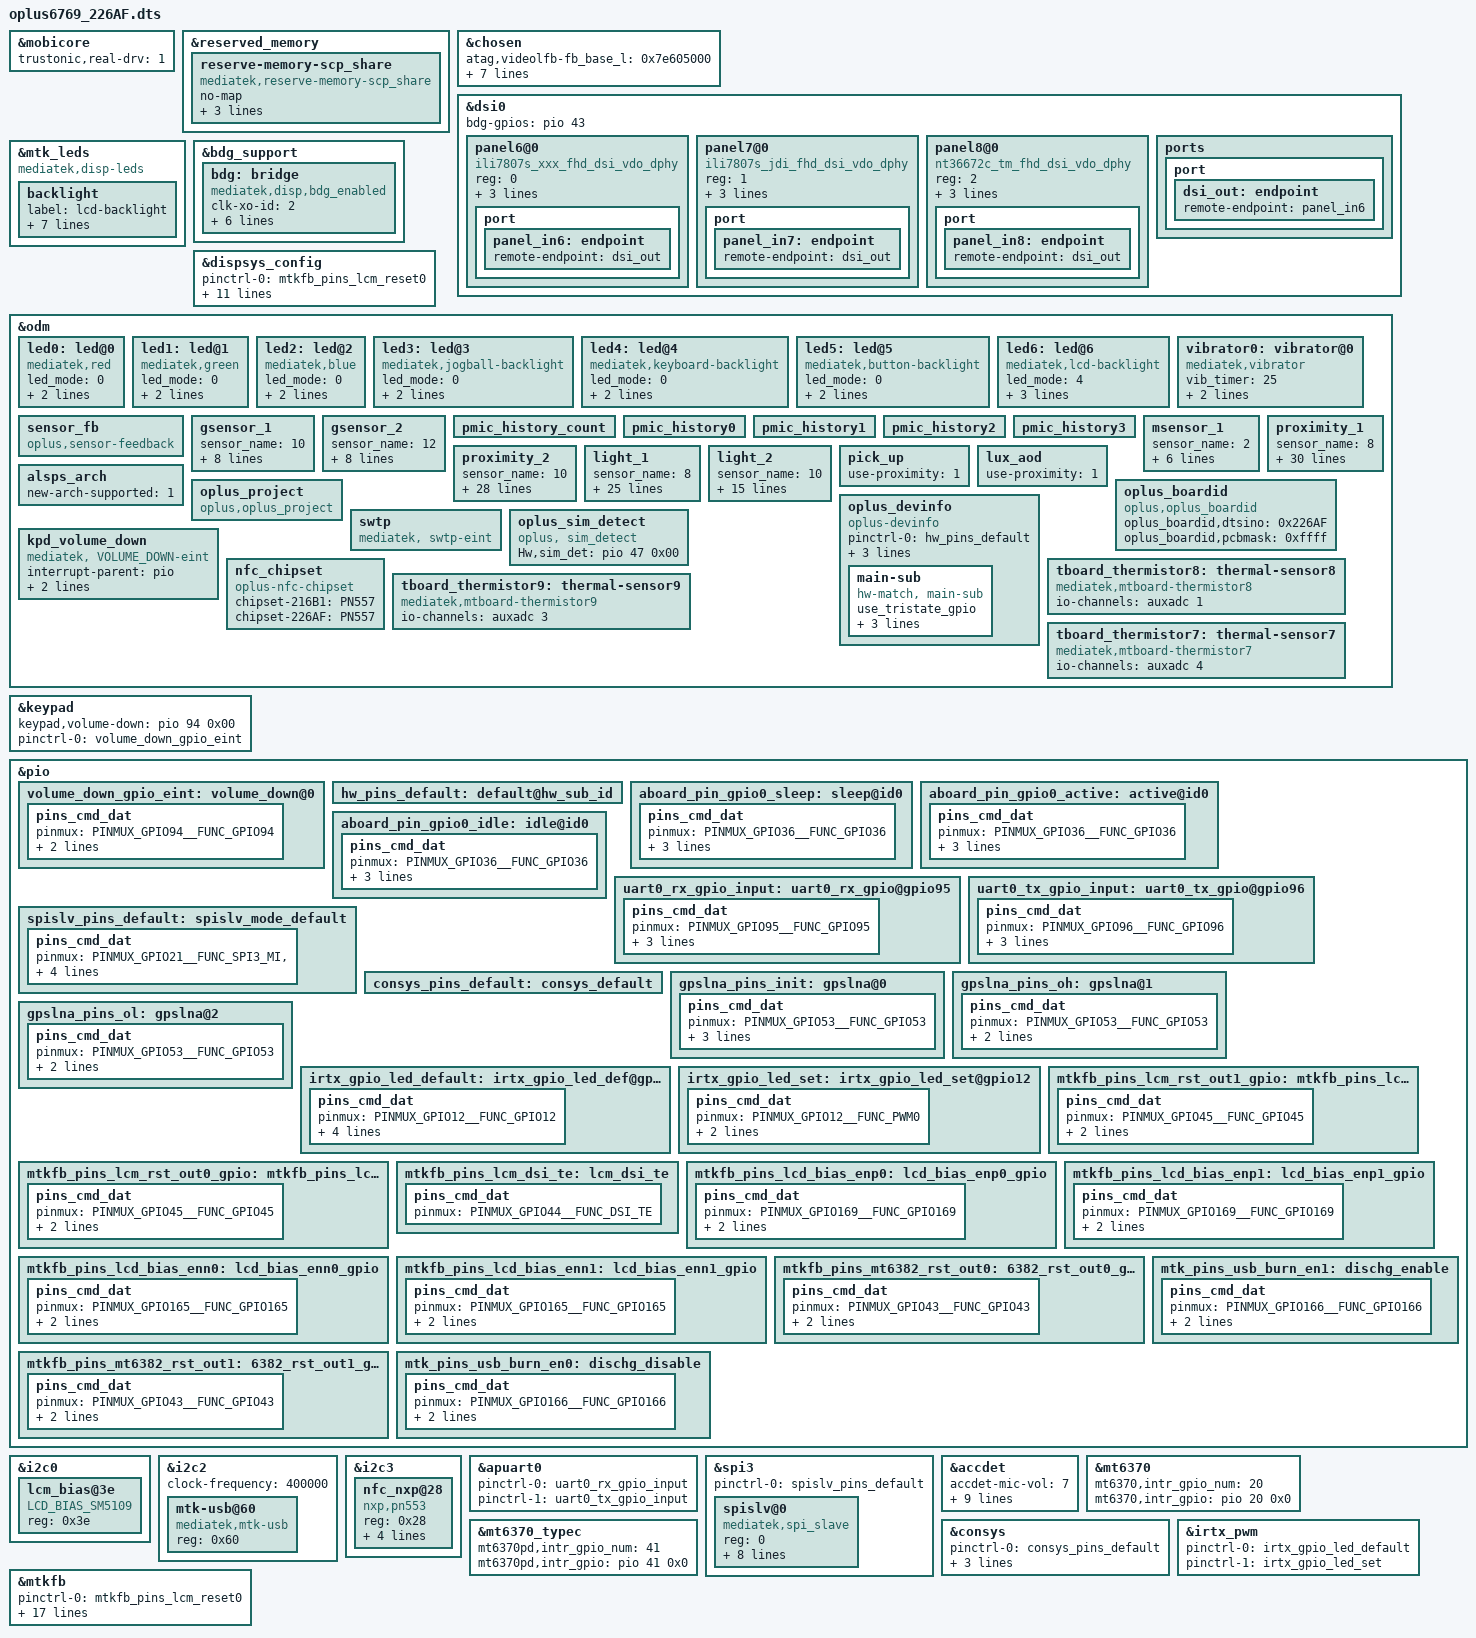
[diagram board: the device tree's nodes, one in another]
/*
 * Copyright (C) 2019 MediaTek Inc.
 *
 * This program is free software; you can redistribute it and/or modify
 * it under the terms of the GNU General Public License version 2 as
 * published by the Free Software Foundation.
 *
 * This program is distributed in the hope that it will be useful,
 * but WITHOUT ANY WARRANTY; without even the implied warranty of
 * MERCHANTABILITY or FITNESS FOR A PARTICULAR PURPOSE.
 * See http://www.gnu.org/licenses/gpl-2.0.html for more details.
 */

/dts-v1/;
/plugin/;
#include <dt-bindings/interrupt-controller/irq.h>
#include <dt-bindings/interrupt-controller/arm-gic.h>
#include <dt-bindings/pinctrl/mt6768-pinfunc.h>
/* Trustonic Mobilecore real driver */
/* #ifdef OPLUS_FEATURE_SECURITY_COMMON */
&mobicore{
     trustonic,real-drv = <1>;
};
/* #endif OPLUS_FEATURE_SECURITY_COMMON */

/* #ifdef CONFIG_UFF_FINGERPRINT */
#include "mediatek/oplus_uff_226AD.dtsi"
/* #endif CONFIG_UFF_FINGERPRINT */

&reserved_memory {
	reserve-memory-scp_share {
		compatible = "mediatek,reserve-memory-scp_share";
		no-map;
		size = <0 0x00d00000>;
		alignment = <0 0x1000000>;
		alloc-ranges = <0 0x40000000 0 0x50000000>;
	};
};

/* chosen */
&chosen {

	atag,videolfb-fb_base_l = <0x7e605000>;
	atag,videolfb-fb_base_h = <0x0>;
	atag,videolfb-islcmfound = <1>;
	atag,videolfb-islcm_inited = <0>;
	atag,videolfb-fps= <6000>;
	atag,videolfb-vramSize= <0x017e8000>;
	atag,videolfb-lcmname=
		"hx83112b_fhdp_dsi_cmd_auo_rt5081_drv";
};

&dsi0 {
	status = "okay";
	#address-cells = <1>;
	#size-cells = <0>;
	bdg-gpios = <&pio 43 0>;
	panel6@0 {
		compatible = "ili7807s_xxx_fhd_dsi_vdo_dphy";
		reg = <0>;
		bdg-support=<1>;
		reset-gpios = <&pio 45 0>;
		bias-gpios = <&pio 169 0>,
				<&pio 165 0>;
		pinctrl-names = "default";
		port {
			panel_in6: endpoint {
				remote-endpoint = <&dsi_out>;
			};
		};
	};

	panel7@0 {
		compatible = "ili7807s_jdi_fhd_dsi_vdo_dphy";
		reg = <1>;
		bdg-support=<1>;
		reset-gpios = <&pio 45 0>;
		bias-gpios = <&pio 169 0>,
				<&pio 165 0>;
		pinctrl-names = "default";
		port {
			panel_in7: endpoint {
				remote-endpoint = <&dsi_out>;
			};
		};
	};
	panel8@0 {
		compatible = "nt36672c_tm_fhd_dsi_vdo_dphy";
		reg = <2>;
		bdg-support=<1>;
		reset-gpios = <&pio 45 0>;
		bias-gpios = <&pio 169 0>,
				<&pio 165 0>;
		pinctrl-names = "default";
		port {
			panel_in8: endpoint {
				remote-endpoint = <&dsi_out>;
			};
		};
	};

	ports {
		port {
			dsi_out: endpoint {
				remote-endpoint = <&panel_in6>;
			};
		};
	};
};
&mtk_leds {
	compatible = "mediatek,disp-leds";
        backlight {
                label = "lcd-backlight";
                max-brightness = <4095>;
                min-brightness = <1>;
                max-hw-brightness = <4095>;
                min-hw-brightness = <1>;
                led-bits = <12>;
                trans-bits = <12>;
                default-state = "on";
        };
};

&bdg_support {
	bdg: bridge {
		compatible = "mediatek,disp,bdg_enabled";
		clk-xo-id = <2>; /* clk pin id: 2 nfc, 6 ext */
        bdg_mm_clk = <270>;
        bdg_rx_v12 = <1720>;
        bdg_rxtx_ratio = <225>;
        hs_dco_enable = <0>;
        lp_tx_l023_enable = <0>;
        g_mode_enable = <0>;
	};
};

&dispsys_config {
	pinctrl-names =
		"lcm_rst_out0_gpio", "lcm_rst_out1_gpio",
		"lcd_bias_enp0_gpio", "lcd_bias_enp1_gpio",
		"lcd_bias_enn0_gpio", "lcd_bias_enn1_gpio",
		"6382_rst_out0_gpio", "6382_rst_out1_gpio";
	pinctrl-0 = <&mtkfb_pins_lcm_reset0>;
	pinctrl-1 = <&mtkfb_pins_lcm_reset1>;
	pinctrl-2 = <&mtkfb_pins_lcd_bias_enp0>;
	pinctrl-3 = <&mtkfb_pins_lcd_bias_enp1>;
	pinctrl-4 = <&mtkfb_pins_lcd_bias_enn0>;
	pinctrl-5 = <&mtkfb_pins_lcd_bias_enn1>;
	pinctrl-6 = <&mtkfb_pins_mt6382_rst_out0>;
	pinctrl-7 = <&mtkfb_pins_mt6382_rst_out1>;
	status = "okay";

	helper-value = <0>, /*MTK_DRM_OPT_STAGE*/
		<1>, /*MTK_DRM_OPT_USE_CMDQ*/
		<1>, /*MTK_DRM_OPT_USE_M4U*/
		<1>, /*MTK_DRM_OPT_MMQOS_SUPPORT*/
		<1>, /*MTK_DRM_OPT_MMDVFS_SUPPORT*/
		<0>, /*MTK_DRM_OPT_SODI_SUPPORT*/
		<1>, /*MTK_DRM_OPT_IDLE_MGR*/
		<0>, /*MTK_DRM_OPT_IDLEMGR_SWTCH_DECOUPLE*/
		<1>, /*MTK_DRM_OPT_IDLEMGR_BY_REPAINT*/
		<0>, /*MTK_DRM_OPT_IDLEMGR_ENTER_ULPS*/
		<0>, /*MTK_DRM_OPT_IDLEMGR_KEEP_LP11*/
		<1>, /*MTK_DRM_OPT_DYNAMIC_RDMA_GOLDEN_SETTING*/
		<1>, /*MTK_DRM_OPT_IDLEMGR_DISABLE_ROUTINE_IRQ*/
		<0>, /*MTK_DRM_OPT_MET_LOG*/
		<1>, /*MTK_DRM_OPT_USE_PQ*/
		<1>, /*MTK_DRM_OPT_ESD_CHECK_RECOVERY*/
		<1>, /*MTK_DRM_OPT_ESD_CHECK_SWITCH*/
		<1>, /*MTK_DRM_OPT_PRESENT_FENCE*/
		<0>, /*MTK_DRM_OPT_RDMA_UNDERFLOW_AEE*/
		<1>, /*MTK_DRM_OPT_DSI_UNDERRUN_AEE*/
		<1>, /*MTK_DRM_OPT_HRT*/
		<1>, /*MTK_DRM_OPT_HRT_MODE*/
		<0>, /*MTK_DRM_OPT_DELAYED_TRIGGER*/
		<1>, /*MTK_DRM_OPT_OVL_EXT_LAYER*/
		<0>, /*MTK_DRM_OPT_AOD*/
		<1>, /*MTK_DRM_OPT_RPO*/
		<0>, /*MTK_DRM_OPT_DUAL_PIPE*/
		<0>, /*MTK_DRM_OPT_DC_BY_HRT*/
		<0>, /*MTK_DRM_OPT_OVL_WCG*/
		<0>, /*MTK_DRM_OPT_OVL_SBCH*/
		<1>, /*MTK_DRM_OPT_COMMIT_NO_WAIT_VBLANK*/
		<0>, /*MTK_DRM_OPT_MET*/
		<0>, /*MTK_DRM_OPT_REG_PARSER_RAW_DUMP*/
		<0>, /*MTK_DRM_OPT_VP_PQ*/
		<0>, /*MTK_DRM_OPT_GAME_PQ*/
		<0>, /*MTK_DRM_OPT_MMPATH*/
		<0>, /*MTK_DRM_OPT_HBM*/
		<0>, /*MTK_DRM_OPT_VDS_PATH_SWITCH*/
		<0>, /*MTK_DRM_OPT_LAYER_REC*/
		<1>, /*MTK_DRM_OPT_CLEAR_LAYER*/
		<0>, /*MTK_DRM_OPT_LFR*/
		<0>, /*MTK_DRM_OPT_SF_PF*/
		<1>, /*MTK_DRM_OPT_DYN_MIPI_CHANGE*/
		<0>, /*MTK_DRM_OPT_PRIM_DUAL_PIPE*/
		<0>, /*MTK_DRM_OPT_MSYNC2_0*/
		<0>, /*MTK_DRM_OPT_MML_PRIMARY*/
		<0>, /*MTK_DRM_OPT_DUAL_TE*/
		<0>, /*MTK_DRM_OPT_VIRTUAL_DISP*/
		<0>, /*MTK_DRM_OPT_RES_SWITCH*/
		<1>, /*MTK_DRM_OPT_SHARE_SRAM*/
		<1>; /*MTK_DRM_OPT_SPHRT*/
};
&odm {
	led0:led@0 {
		compatible = "mediatek,red";
		led_mode = <0>;
		data = <1>;
		pwm_config = <0 0 0 0 0>;
	};
	led1:led@1 {
		compatible = "mediatek,green";
		led_mode = <0>;
		data = <1>;
		pwm_config = <0 0 0 0 0>;
	};
	led2:led@2 {
		compatible = "mediatek,blue";
		led_mode = <0>;
		data = <1>;
		pwm_config = <0 0 0 0 0>;
	};
	led3:led@3 {
		compatible = "mediatek,jogball-backlight";
		led_mode = <0>;
		data = <1>;
		pwm_config = <0 0 0 0 0>;
	};
	led4:led@4 {
		compatible = "mediatek,keyboard-backlight";
		led_mode = <0>;
		data = <1>;
		pwm_config = <0 0 0 0 0>;
	};
	led5:led@5 {
		compatible = "mediatek,button-backlight";
		led_mode = <0>;
		data = <1>;
		pwm_config = <0 0 0 0 0>;
	};
	led6:led@6 {
		compatible = "mediatek,lcd-backlight";
		//#indef OPLUS_BUG_COMPATIBILITY
		//led_mode = <5>;
		//#else
		led_mode = <4>;
		led_rm = <1>;
		//#endif
		data = <1>;
		pwm_config = <0 3 0 0 0>;
	};
	vibrator0:vibrator@0 {
		compatible = "mediatek,vibrator";
		vib_timer = <25>;
		vib_limit = <9>;
		vib_vol= <11>;
	};
/* sensor start */
	sensor_fb: sensor_fb {
		compatible = "oplus,sensor-feedback";
	};
	/*
	enum {
		LIS3DH,
		LSM6DS3,
		BMI160,
		LIS2HH12,
		LSM6DSM,
		BMI2XY,
		LSM6DSO,
		ICM4X6XX,
		MA2X2,
		KX022,
		SC7A20,
		ICM4N607,
		BMA4XY,
		MC34X9,
	};
	*/
	gsensor_1: gsensor_1 {
		status = "okay";
		sensor_name = <10>;//SC7A20
		i2c_num = <1>;
		i2c_addr = <0>;
		direction = <0>;
		eint_num = <2>;
		step_count_7_en = <1>;
		config_miso = <1>;
		correct_y_bias = <1>;
		acc_cali_range= <300 300 300>; //300mg
	};
	gsensor_2: gsensor_2 {
		status = "okay";
		sensor_name = <12>;//BMA4XY
		i2c_num = <1>;
		i2c_addr = <0>;
		direction = <9>;
		eint_num = <2>;
		step_count_7_en = <1>;
		config_miso = <1>;
		correct_y_bias = <1>;
		acc_cali_range= <300 300 300>; //300mg
	};
	/*
	enum {
		AKM09911,
		MMC3530,
		MMC5603,
		MXG4300,
	};
	*/

	pmic_history_count:pmic_history_count {
	};
	pmic_history0:pmic_history0 {
	};
	pmic_history1:pmic_history1 {
	};
	pmic_history2:pmic_history2 {
	};
	pmic_history3:pmic_history3 {
	};

    msensor_1: msensor_1 {
        status = "okay";
        sensor_name = <2>;//MMC5603
        i2c_num = <0>;
        i2c_addr = <0x30>;
        direction = <0>;
        eint_num = <0>;
        soft-mag-parameter = <9995 0 245 1 184 1 52 1 10853 0 5 1 24 1 1281 1 11542 0>;
    };
	/*
	enum {
		TMD2725,
		APSD9922,
		STK3335,
		STK3331,
		STK2232,
		TCS3701,
		STK32600,
		STK33502,
		MN78911,
		TMD2755x12,
		STK33C01,
	};
	*/
	proximity_1: proximity_1 {
		status = "okay";
		sensor_name = <8>;//MN78911
		i2c_num = <0>;
		i2c_addr = <0x41>;
		direction = <4>;
		eint_num = <10>;
		low_step = <300>;
		high_step = <400>;
		low_limit = <650>;
		high_limit = <1050>;
		dirty_low_step = <300>;
		dirty_high_step = <400>;
		ps_dirty_limit = <1800>;
		ps_ir_limit = <2000>;
		ps_adjust_min = <0>;
		ps_adjust_max = <1850>;
		sampling_count = <5>;
		step_max = <400>;
		step_min = <100>;
		step_div = <2200>;
		anti_shake_delta = <70>;
		dynamic_cali_max = <2000>;
		raw2offset_radio = <1000>;
		offset_max = <60000>;
		offset_range_min = <0>;
		offset_range_max = <65534>;
		force_cali_limit = <2000>;
		cali_jitter_limit = <30>;
		cal_offset_margin = <3000>;
		is_use_force_cali = <1>;
		enable_low_threshold = <5000>;
		enable_high_threshold = <5001>;
	};
	proximity_2: proximity_2 {
		status = "okay";
		sensor_name = <10>;//STK33C01
		i2c_num = <0>;
		i2c_addr = <0x48>;
		direction = <4>;
		eint_num = <10>;
		low_step = <300>;
		high_step = <400>;
		low_limit = <650>;
		high_limit = <1050>;
		dirty_low_step = <300>;
		dirty_high_step = <400>;
		ps_dirty_limit = <1800>;
		ps_ir_limit = <2000>;
		ps_adjust_min = <0>;
		ps_adjust_max = <1850>;
		sampling_count = <5>;
		step_max = <400>;
		step_min = <100>;
		step_div = <2000>;
		anti_shake_delta = <70>;
		dynamic_cali_max = <2000>;
		raw2offset_radio = <1000>;
		offset_max = <60000>;
		offset_range_min = <0>;
		offset_range_max = <65534>;
		force_cali_limit = <2000>;
		cali_jitter_limit = <30>;
		cal_offset_margin = <3000>;
		is_use_force_cali = <1>;
	};
	light_1: light_1 {
		status = "okay";
		sensor_name = <8>;//MN78911
		i2c_num = <0>;
		i2c_addr = <0x41>;
		direction = <4>;
		eint_num = <10>;
		als_ratio = <110>;
		als_buffer_length =<8>;
		als_type = <1>;//<1-normal;2-under screen;3-normal needed compensation>
		device_name = "mn78911";
		lsrc_algr_way = <1>;
		cwf_ratio_thd = <200>;
		d65_ratio_thd = <900>;
		a_ratio_thd = <1600>;
		d65_factor = <890>;
		a_factor = <800>;
		hz_factor = <1000>;
		offset_gain = <310>;
		scale_gain = <290>;
		offset_gain_2 = <380>;
		scale_gain_2 = <235>;
		lsrc_coe = <1200>;
		lux_revocer = <7000>;
		low_lux_h_thd = <10>;
		low_lux_l_thd = <2>;
		low_lux_ext = <0>;
		low_lux_ratio = <1600>;
	};
	light_2: light_2 {
		status = "okay";
		sensor_name = <10>;//STK33C01
		i2c_num = <0>;
		i2c_addr = <0x48>;
		direction = <4>;
		eint_num = <10>;
		als_ratio = <210>;
		als_buffer_length =<8>;
		als_type = <1>;//<1-normal;2-under screen;3-normal needed compensation>
		device_name = "stk33c01";
		coefficient_mode = <6>;
		als_coef_a = <1552>; //*100
		als_coef_b = <125>; //*100
		als_coef_c = <1552>; //*100
		als_coef_d = <125>; //*100
		als_coef_e = <2490>; //*100
		als_coef_ratio = <1500>;
	};
	pick_up: pick_up {
		status = "okay";
		use-proximity = <1>;
	};
	lux_aod: lux_aod {
		status = "okay";
		use-proximity = <1>;
	};
	alsps_arch: alsps_arch {
		status = "okay";
		new-arch-supported = <1>;
	};
/* sensor end */
/*VNDOR_EDIT oppo project start */
	oplus_project:oplus_project {
		compatible = "oplus,oplus_project";
	};


	oplus_boardid:oplus_boardid {
		compatible = "oplus,oplus_boardid";
		oplus_boardid,dtsino="0x226AF";//only one u32
		oplus_boardid,pcbmask="0xffff";//all mask 0xffff
	};

	oplus_devinfo:oplus_devinfo {
		compatible = "oplus-devinfo";
		pinctrl-names = "default", "aboard_gpio0_sleep", "aboard_gpio0_active", "aboard_gpio0_idle";
        	pinctrl-0 = <&hw_pins_default>;
		pinctrl-1 = <&aboard_pin_gpio0_sleep>;
		pinctrl-2 = <&aboard_pin_gpio0_active>;
		pinctrl-3 = <&aboard_pin_gpio0_idle>;
                main-sub {
			use_tristate_gpio;
                        compatible = "hw-match, main-sub";
			aboard-gpio0 = <&pio 36 0x00>;
                        aboard-patterns = <0 1 1>;
                        /*main board*/
                        match-projects = <140973 140974 140975 140976>;
                };
	};
//#ifdef OPLUS_BUG_COMPATIBILITY
	swtp:swtp {
		compatible = "mediatek, swtp-eint";
	};
//#endif /*OPLUS_BUG_COMPATIBILITY*/

//#ifdef OPLUS_FEATURE_SIM
	oplus_sim_detect {
		compatible = "oplus, sim_detect";
		Hw,sim_det = <&pio 47 0x00>;
	};
//#endif /* OPLUS_FEATURE_SIM */

//ifdef OPLUS_BUG_STABILITY
	kpd_volume_down:kpd_volume_down {
		compatible = "mediatek, VOLUME_DOWN-eint";
		interrupt-parent = <&pio>;
		interrupts = <94 IRQ_TYPE_EDGE_FALLING 94 0>;
		debounce = <32000>;
		status = "okay";
	};
//#endif /*OPLUS_BUG_STABILITY*/

    //#ifdef OPLUS_FEATURE_NFC_CONSOFT
    nfc_chipset:nfc_chipset {
        compatible = "oplus-nfc-chipset";
        chipset-216B1 = "PN557";
	chipset-226AF = "PN557";
    };
    //#endif /* OPLUS_FEATURE_NFC_CONSOFT */
	tboard_thermistor8: thermal-sensor8 {
		compatible = "mediatek,mtboard-thermistor8";
		io-channels = <&auxadc 1>;
		io-channel-names = "thermistor-ch1";
 	};
 	tboard_thermistor9: thermal-sensor9 {
 		compatible = "mediatek,mtboard-thermistor9";
 		io-channels = <&auxadc 3>;
 		io-channel-names = "thermistor-ch3";
 	};
 	tboard_thermistor7: thermal-sensor7 {
 		compatible = "mediatek,mtboard-thermistor7";
 		io-channels = <&auxadc 4>;
 		io-channel-names = "thermistor-ch4";
 	};

};

//ifdef OPLUS_BUG_STABILITY
&keypad {
	keypad,volume-down	= <&pio 94 0x00>;
	pinctrl-names = "volume_down_as_int";
	pinctrl-0 = <&volume_down_gpio_eint>;
	status = "okay";
};

&pio {
	volume_down_gpio_eint:volume_down@0{
		pins_cmd_dat {
			pinmux = <PINMUX_GPIO94__FUNC_GPIO94>;
			slew-rate = <0>;  /*direction 0:in, 1:out*/
			input-enable;
		};
	};
};
//#endif /*OPLUS_BUG_STABILITY*/
/*&i2c_common {
	ext_time_config = /bits/ 16 <0x1A01>;
};*/

&i2c0 {
      lcm_bias@3e{
               compatible = "LCD_BIAS_SM5109","LCD_BIAS_OCP2130";
               reg = <0x3e>;
               status = "okay";
       };
};

&i2c2 {
	clock-frequency = <400000>;

	mtk-usb@60 {
		compatible = "mediatek,mtk-usb";
		reg = <0x60>;
		status = "okay";
	};
};

&i2c3 {
       status = "okay";
       nfc_nxp@28 {
               compatible = "nxp,pn553";
               reg = <0x28>;
               nxp,pn544-irq = <&pio 6 0x0>;
               nxp,pn544-ven = <&pio 8 0x0>;
               nxp,pn544-fw-dwnld = <&pio 19 0x0>;
               //pn544-clkreq = <&pio 11 0x0>;
               interrupt-parent = <&pio>;
       };
};


//#ifdef OPLUS_FEATURE_CHG_BASIC
&apuart0 {
	pinctrl-names = "uart0_rx_gpio",
			"uart0_tx_gpio";
	pinctrl-0 = <&uart0_rx_gpio_input>;
	pinctrl-1 = <&uart0_tx_gpio_input>;
	status = "okay";
};
&pio {
	hw_pins_default:default@hw_sub_id {
	};

	aboard_pin_gpio0_sleep:sleep@id0 {
		pins_cmd_dat {
			pinmux = <PINMUX_GPIO36__FUNC_GPIO36>;
			slew-rate = <0>;
			bias-pull-down;
			input-enable;
		};
	};

	aboard_pin_gpio0_active:active@id0 {
		pins_cmd_dat {
			pinmux = <PINMUX_GPIO36__FUNC_GPIO36>;
			slew-rate = <0>;
			bias-pull-up;
			input-enable;
		};
	};

	aboard_pin_gpio0_idle:idle@id0 {
		pins_cmd_dat {
			pinmux = <PINMUX_GPIO36__FUNC_GPIO36>;
			slew-rate = <0>;
			bias-disable;
			input-enable;
		};
	};
};

&pio {
	uart0_rx_gpio_input:uart0_rx_gpio@gpio95 {
		pins_cmd_dat {
			pinmux = <PINMUX_GPIO95__FUNC_GPIO95>;
			input-enable;
			slew-rate = <0>;
			bias-disable;
		};
	};
	uart0_tx_gpio_input:uart0_tx_gpio@gpio96 {
		pins_cmd_dat {
			pinmux = <PINMUX_GPIO96__FUNC_GPIO96>;
			input-enable;
			slew-rate = <0>;
			bias-disable;
		};
	};
};

&spi3 {
	status = "okay";
	#address-cells = <1>;
	#size-cells = <0>;
	pinctrl-names = "default";
	pinctrl-0 = <&spislv_pins_default>;

	//mediatek,kthread-rt = <1>;

	spislv@0 {
		compatible = "mediatek,spi_slave";
		reg = <0>;
		spi-max-frequency = <55000000>;
		spi-tx-bus-width = <1>;
		spi-rx-bus-width = <1>;
		low-speed-tick-delay = /bits/ 8 <4>;
		low-speed-early-trans = /bits/ 8 <0>;
		high-speed-tick-delay = /bits/ 8 <2>;
		high-speed-early-trans = /bits/ 8 <0>;
		slave-drive-strength = /bits/ 8 <3>;
	};
};

&pio {
	spislv_pins_default: spislv_mode_default {
		pins_cmd_dat {
			pinmux = <PINMUX_GPIO21__FUNC_SPI3_MI>,
					<PINMUX_GPIO22__FUNC_SPI3_CSB>,
					<PINMUX_GPIO23__FUNC_SPI3_MO>,
					<PINMUX_GPIO24__FUNC_SPI3_CLK>;
					 drive-strength = <3>;
				};
	};
};

/* accdet start */
&accdet {
	/* accdet micbias voltage: 0x07,2.7v;0x05,2.5v;0x02,1.9v */
	accdet-mic-vol = <7>;
	headset-mode-setting = <0x500 0x500 1 0x1f0 0x800 0x800 0x20 0x44>;
	accdet-plugout-debounce = <1>;
	/*1:ACC mode, 2:low cost without in bias, 6:low cost with in bias*/
	accdet-mic-mode = <1>;
	/* eint_level_trigger: 8,LEVEL_LOW(DEF) ;4,LV_HIGH;others,LV_LOW */
	headset-eint-level-pol = <8>;
//#ifdef OPLUS_BUG_COMPATIBILITY
	headset-eint-comparator = <8>;
//#endif
	/*0--MD_MAX--UP_MAX--DW_MAX*/
	headset-three-key-threshold = <0 82 170 306>;
	headset-three-key-threshold-CDD = <0 121 192 600>;
	/*0--MD_MAX--VOICE_MAX--UP_MAX--DW_MAX*/
	headset-four-key-threshold = <0 58 121 192 400>;
	status = "okay";
};
/* accdet end */

&mt6370 {
	mt6370,intr_gpio_num = <20>; /* direct defined GPIO num */
	mt6370,intr_gpio = <&pio 20 0x0>;
};
&mt6370_typec {
	mt6370pd,intr_gpio_num = <41>; /* direct defined GPIO num */
	mt6370pd,intr_gpio = <&pio 41 0x0>;
};

/* CONSYS GPIO standardization */
&pio {
	consys_pins_default: consys_default {
	};
	//#ifdef OPLUS_BUG_STABILITY
	gpslna_pins_init: gpslna@0 {
		pins_cmd_dat {
			pinmux = <PINMUX_GPIO53__FUNC_GPIO53>;
			slew-rate = <0>;
			bias-disable;
			output-low;
		};
	};
	gpslna_pins_oh: gpslna@1 {
		pins_cmd_dat {
			pinmux = <PINMUX_GPIO53__FUNC_GPIO53>;
			slew-rate = <1>;
			output-high;
		};
	};
	gpslna_pins_ol: gpslna@2 {
		pins_cmd_dat {
			pinmux = <PINMUX_GPIO53__FUNC_GPIO53>;
			slew-rate = <1>;
			output-low;
		};
	};
	//#endif /* OPLUS_BUG_STABILITY */
};
&consys {
	pinctrl-names = "default", "gps_lna_state_init",
		"gps_lna_state_oh", "gps_lna_state_ol";
	pinctrl-0 = <&consys_pins_default>;
	pinctrl-1 = <&gpslna_pins_init>;
	pinctrl-2 = <&gpslna_pins_oh>;
	pinctrl-3 = <&gpslna_pins_ol>;
	status = "okay";
};
/* CONSYS end */

/* IRTX GPIO Start */
&irtx_pwm {
	pinctrl-names = "irtx_gpio_led_default", "irtx_gpio_led_set";
	pinctrl-0 = <&irtx_gpio_led_default>;
	pinctrl-1 = <&irtx_gpio_led_set>;
	status = "okay";
};
&pio {
	/* IRTX GPIO Settings -Start */
	/* default: GPIO0, output, high */
	irtx_gpio_led_default:irtx_gpio_led_def@gpio12 {
		pins_cmd_dat {
			pinmux = <PINMUX_GPIO12__FUNC_GPIO12>;
			slew-rate = <1>;
			bias-disable;
			output-low;
			input-schmitt-enable = <0>;
		};
	};

	irtx_gpio_led_set:irtx_gpio_led_set@gpio12 {
		pins_cmd_dat {
			pinmux = <PINMUX_GPIO12__FUNC_PWM0>;
			slew-rate = <1>;
			output-high;
		};
	};
}; /* IRTX GPIO Settings -End */

/* DISPSYS GPIO standardization */
&pio {
	mtkfb_pins_lcm_rst_out1_gpio: lcm_rst_out1_gpio {
		pins_cmd_dat {
			pinmux = <PINMUX_GPIO45__FUNC_GPIO45>;
			slew-rate = <1>;
			output-high;
		};
	};

	mtkfb_pins_lcm_rst_out0_gpio: lcm_rst_out0_gpio {
		pins_cmd_dat {
			pinmux = <PINMUX_GPIO45__FUNC_GPIO45>;
			slew-rate = <1>;
			output-low;
		};
	};

	mtkfb_pins_lcm_dsi_te: lcm_dsi_te {
		pins_cmd_dat {
			pinmux = <PINMUX_GPIO44__FUNC_DSI_TE>;
		};
	};
};

/*&mtkfb {
	pinctrl-names =
		"lcm_rst_out1_gpio", "lcm_rst_out0_gpio",
		"mode_te_te";
	pinctrl-0 = <&mtkfb_pins_lcm_rst_out1_gpio>;
	pinctrl-1 = <&mtkfb_pins_lcm_rst_out0_gpio>;
	pinctrl-2 = <&mtkfb_pins_lcm_dsi_te>;
	status = "okay";
};*/
/* DISPSYS GPIO standardization */
&mtkfb {
        pinctrl-names = "lcm_rst_out0_gpio", "lcm_rst_out1_gpio", "lcd_bias_enp0_gpio", "lcd_bias_enp1_gpio",
			"lcd_bias_enn0_gpio", "lcd_bias_enn1_gpio", "6382_rst_out0_gpio", "6382_rst_out1_gpio";

	pinctrl-0 = <&mtkfb_pins_lcm_reset0>;
	pinctrl-1 = <&mtkfb_pins_lcm_reset1>;
	pinctrl-2 = <&mtkfb_pins_lcd_bias_enp0>;
	pinctrl-3 = <&mtkfb_pins_lcd_bias_enp1>;
	pinctrl-4 = <&mtkfb_pins_lcd_bias_enn0>;
	pinctrl-5 = <&mtkfb_pins_lcd_bias_enn1>;
	pinctrl-6 = <&mtkfb_pins_mt6382_rst_out0>;
	pinctrl-7 = <&mtkfb_pins_mt6382_rst_out1>;
        status = "okay";
	oplus_display_twelvebits_support;
	oplus_display_cabc_support;
	oplus_display_cabc_cmdq_support;
	oplus_display_panelnum_support;
	oplus_display_mt6382_support;
	oplus_display_no_support_mtk_round_corner;
	oplus_display_mt6382_esd_check;
	oplus_display_async_bl_support;
	oplus_display_normal_max_brightness = <2047>;
	mininum_brightness = <14>;
};


&pio {
        mtkfb_pins_lcm_reset0: lcm_rst_out0_gpio {
                pins_cmd_dat {
                        pinmux = <PINMUX_GPIO45__FUNC_GPIO45>;
                        slew-rate = <1>;
                        output-low;
                };
        };
        mtkfb_pins_lcm_reset1: lcm_rst_out1_gpio {
                pins_cmd_dat {
                        pinmux = <PINMUX_GPIO45__FUNC_GPIO45>;
                        slew-rate = <1>;
                        output-high;
                };
        };

	mtkfb_pins_lcd_bias_enp0: lcd_bias_enp0_gpio {
                pins_cmd_dat {
                        pinmux = <PINMUX_GPIO169__FUNC_GPIO169>;
                        slew-rate = <1>;
                        output-low;
                };
        };
	mtkfb_pins_lcd_bias_enp1: lcd_bias_enp1_gpio {
                pins_cmd_dat {
                        pinmux = <PINMUX_GPIO169__FUNC_GPIO169>;
                        slew-rate = <1>;
                        output-high;
                };
        };

	mtkfb_pins_lcd_bias_enn0: lcd_bias_enn0_gpio {
                pins_cmd_dat {
                        pinmux = <PINMUX_GPIO165__FUNC_GPIO165>;
                        slew-rate = <1>;
                        output-low;
                };
        };
	mtkfb_pins_lcd_bias_enn1: lcd_bias_enn1_gpio {
                pins_cmd_dat {
                        pinmux = <PINMUX_GPIO165__FUNC_GPIO165>;
                        slew-rate = <1>;
                        output-high;
                };
        };

	mtkfb_pins_mt6382_rst_out0: 6382_rst_out0_gpio {
                pins_cmd_dat {
                        pinmux = <PINMUX_GPIO43__FUNC_GPIO43>;
                        slew-rate = <1>;
                        output-low;
                };
        };
	mtkfb_pins_mt6382_rst_out1: 6382_rst_out1_gpio {
                pins_cmd_dat {
                        pinmux = <PINMUX_GPIO43__FUNC_GPIO43>;
                        slew-rate = <1>;
                        output-high;
                };
        };

/*	mtkfb_pins_lcd_vddio18_en0: lcd_vddio18_en0_gpio {
                pins_cmd_dat {
                        pinmux = <PINMUX_GPIO170__FUNC_GPIO170>;
                        slew-rate = <1>;
                        output-low;
                };
        };
	mtkfb_pins_lcd_vddio18_en1: lcd_vddio18_en1_gpio {
                pins_cmd_dat {
                        pinmux = <PINMUX_GPIO170__FUNC_GPIO170>;
                        slew-rate = <1>;
                        output-high;
                };
        };*/
};


/* DISPSYS GPIO standardization end*/


&pio {
		mtk_pins_usb_burn_en0: dischg_disable{
                pins_cmd_dat {
                        pinmux = <PINMUX_GPIO166__FUNC_GPIO166>;
                        slew-rate = <1>;
                        output-low;
                };
		};

		mtk_pins_usb_burn_en1: dischg_enable{
                pins_cmd_dat {
                        pinmux = <PINMUX_GPIO166__FUNC_GPIO166>;
                        slew-rate = <1>;
                        output-high;
                };
		};
};
#include "mediatek/oplus6769_charger_226AF.dtsi"
#include <oplus6769_226AF/cust.dtsi>
#include "mediatek/cust_mt6769_camera_miami.dtsi"
#include "mediatek/cust_mt6769_touch_1080x2400.dtsi"
#include "mediatek/cust_mt6769_sia8102.dtsi"
//#include "mediatek/cust_mt6768_touch_1080x2160.dtsi"
/*End of this file, DO NOT ADD ANYTHING HERE*/
